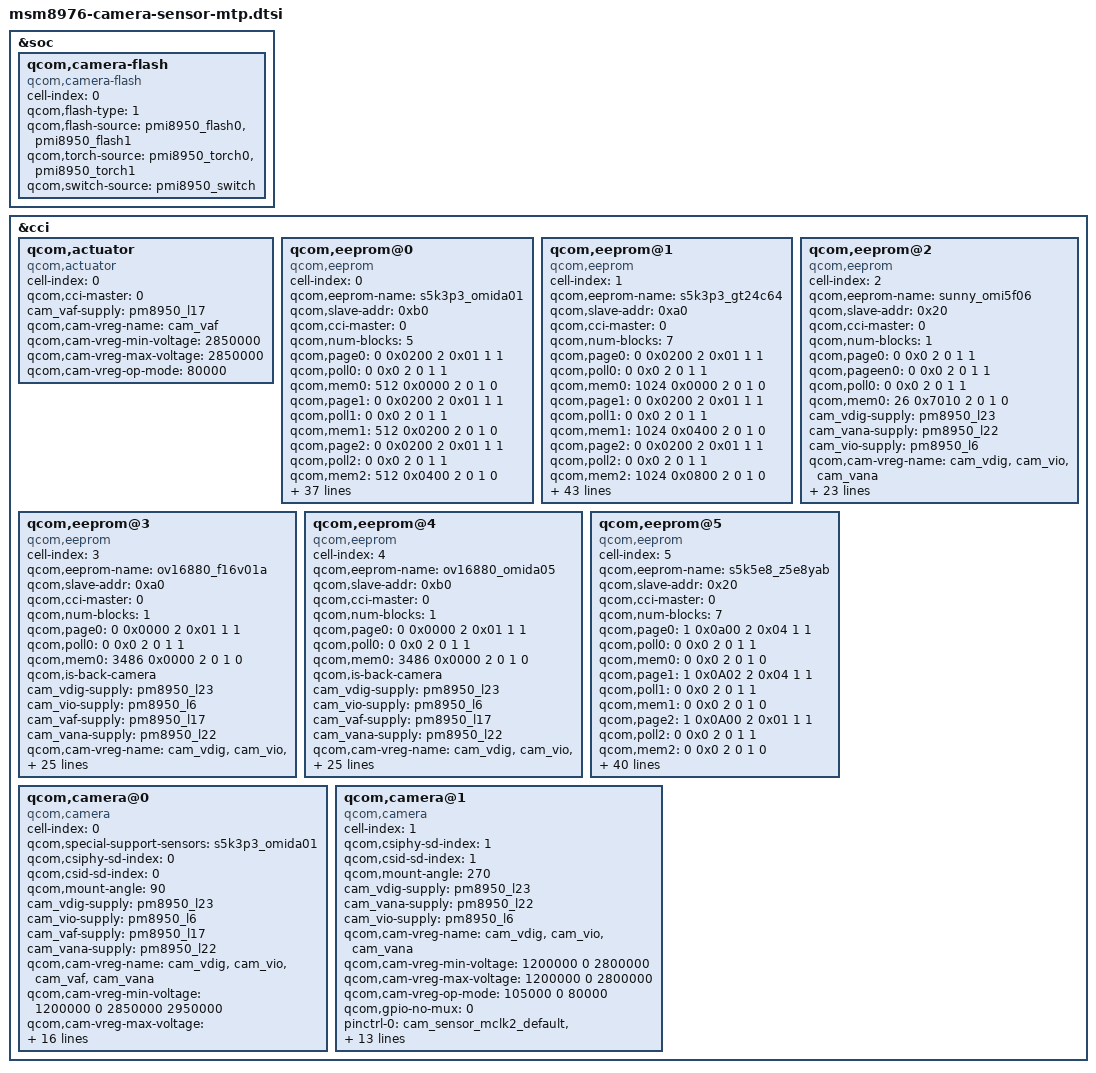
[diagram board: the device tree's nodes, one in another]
// SPDX-License-Identifier: GPL-2.0
// Copyright (c) 2015, The Linux Foundation. All rights reserved.
// Copyright (c) 2023, Benarji Anand <benarji385@gmail.com>

&soc {
	qcom,camera-flash {
		cell-index = <0>;
		compatible = "qcom,camera-flash";
		qcom,flash-type = <1>;
		qcom,flash-source = <&pmi8950_flash0 &pmi8950_flash1>;
		qcom,torch-source = <&pmi8950_torch0 &pmi8950_torch1>;
		qcom,switch-source = <&pmi8950_switch>;
	};
};

&cci {
	qcom,actuator {
		cell-index = <0>;
		compatible = "qcom,actuator";
		qcom,cci-master = <0>;
		cam_vaf-supply = <&pm8950_l17>;
		qcom,cam-vreg-name = "cam_vaf";
		qcom,cam-vreg-min-voltage = <2850000>;
		qcom,cam-vreg-max-voltage = <2850000>;
		qcom,cam-vreg-op-mode = <80000>;
	};

	qcom,eeprom@0{
		cell-index = <0>;
		qcom,eeprom-name = "s5k3p3_omida01";
		compatible = "qcom,eeprom";
		qcom,slave-addr = <0xb0>;
		qcom,cci-master = <0>;
		qcom,num-blocks = <5>;

		qcom,page0  = <0 0x0200 2 0x01 1 1>;
		qcom,poll0  = <0 0x0 2 0 1 1>;
		qcom,mem0   = <512 0x0000 2 0 1 0>;

		qcom,page1  = <0 0x0200 2 0x01 1 1>;
		qcom,poll1  = <0 0x0 2 0 1 1>;
		qcom,mem1   = <512 0x0200 2 0 1 0>;

		qcom,page2  = <0 0x0200 2 0x01 1 1>;
		qcom,poll2  = <0 0x0 2 0 1 1>;
		qcom,mem2   = <512 0x0400 2 0 1 0>;

		qcom,page3  = <0 0x0200 2 0x01 1 1>;
		qcom,poll3  = <0 0x0 2 0 1 1>;
		qcom,mem3   = <512 0x0600 2 0 1 0>;

		qcom,page4  = <0 0x0200 2 0x01 1 1>;
		qcom,poll4  = <0 0x0 2 0 1 1>;
		qcom,mem4   = <512 0x0800 2 0 1 0>;
		qcom,is-back-camera;
		cam_vdig-supply = <&pm8950_l23>;
		cam_vio-supply = <&pm8950_l6>;
		cam_vaf-supply = <&pm8950_l17>;
		cam_vana-supply = <&pm8950_l22>;  /*must add at last vreg*/
		qcom,cam-vreg-name = "cam_vdig", "cam_vio", "cam_vaf","cam_vana";
		qcom,cam-vreg-min-voltage = <1200000 0 2850000 2850000>;
		qcom,cam-vreg-max-voltage = <1200000 0 2850000 2850000>;
		qcom,cam-vreg-op-mode = <200000 0 100000 100000>;
		pinctrl-names = "cam_default", "cam_suspend";
		pinctrl-0 = <&cam_sensor_mclk0_default
				&cam_sensor_rear_default>;
		pinctrl-1 = <&cam_sensor_mclk0_sleep &cam_sensor_rear_sleep>;
		gpios = <&tlmm 26 0>,
			<&tlmm 129 0>,
			<&tlmm 123 0>;
		qcom,gpio-reset = <1>;
		qcom,gpio-vana = <2>;
		qcom,gpio-req-tbl-num = <0 1 2>;
		qcom,gpio-req-tbl-flags = <1 0 0>;
		qcom,gpio-req-tbl-label = "CAMIF_MCLK0",
			"CAM_RESET",
			"CAM_STANDBY";

		qcom,cam-power-seq-type = "sensor_vreg",
			"sensor_vreg", "sensor_vreg",
			"sensor_gpio", "sensor_gpio",
			"sensor_clk";
		qcom,cam-power-seq-val = "cam_vio",
			"cam_vana", "cam_vdig",
			"sensor_gpio_reset",
			"sensor_gpio_standby",
			"sensor_cam_mclk" ;
		qcom,cam-power-seq-cfg-val = <1 1 1 1 1 24000000>;
		qcom,cam-power-seq-delay = <5 5 5 5 5 5>;
	};

	qcom,eeprom@1{
		cell-index = <1>;
		qcom,eeprom-name = "s5k3p3_gt24c64";
		compatible = "qcom,eeprom";
		qcom,slave-addr = <0xa0>;
		qcom,cci-master = <0>;
		qcom,num-blocks = <7>;

		qcom,page0  = <0 0x0200 2 0x01 1 1>;
		qcom,poll0  = <0 0x0 2 0 1 1>;
		qcom,mem0   = <1024 0x0000 2 0 1 0>;

		qcom,page1  = <0 0x0200 2 0x01 1 1>;
		qcom,poll1  = <0 0x0 2 0 1 1>;
		qcom,mem1   = <1024 0x0400 2 0 1 0>;

		qcom,page2  = <0 0x0200 2 0x01 1 1>;
		qcom,poll2  = <0 0x0 2 0 1 1>;
		qcom,mem2   = <1024 0x0800 2 0 1 0>;

		qcom,page3  = <0 0x0200 2 0x01 1 1>;
		qcom,poll3  = <0 0x0 2 0 1 1>;
		qcom,mem3   = <1024 0x0c00 2 0 1 0>;

		qcom,page4  = <0 0x0200 2 0x01 1 1>;
		qcom,poll4  = <0 0x0 2 0 1 1>;
		qcom,mem4   = <1024 0x1000 2 0 1 0>;

		qcom,page5  = <0 0x0200 2 0x01 1 1>;
		qcom,poll5  = <0 0x0 2 0 1 1>;
		qcom,mem5   = <1024 0x1400 2 0 1 0>;

		qcom,page6  = <0 0x0200 2 0x01 1 1>;
		qcom,poll6  = <0 0x0 2 0 1 1>;
		qcom,mem6   = <1024 0x1800 2 0 1 0>;
		qcom,is-back-camera;
		cam_vdig-supply = <&pm8950_l23>;
		cam_vio-supply = <&pm8950_l6>;
		cam_vaf-supply = <&pm8950_l17>;
		cam_vana-supply = <&pm8950_l22>;  /*must add at last vreg*/
		qcom,cam-vreg-name = "cam_vdig", "cam_vio", "cam_vaf","cam_vana";
		qcom,cam-vreg-min-voltage = <1200000 0 2850000 2850000>;
		qcom,cam-vreg-max-voltage = <1200000 0 2850000 2850000>;
		qcom,cam-vreg-op-mode = <200000 0 100000 100000>;

		pinctrl-names = "cam_default", "cam_suspend";
		pinctrl-0 = <&cam_sensor_mclk0_default
				&cam_sensor_rear_default>;
		pinctrl-1 = <&cam_sensor_mclk0_sleep &cam_sensor_rear_sleep>;

		gpios = <&tlmm 26 0>,
			<&tlmm 129 0>,
			<&tlmm 123 0>;
		qcom,gpio-reset = <1>;
	        qcom,gpio-vana = <2>;
		qcom,gpio-req-tbl-num = <0 1 2>;
		qcom,gpio-req-tbl-flags = <1 0 0>;
		qcom,gpio-req-tbl-label = "CAMIF_MCLK0",
			"CAM_RESET",
			"CAM_STANDBY";

		qcom,cam-power-seq-type = "sensor_vreg",
			"sensor_vreg", "sensor_vreg",
			"sensor_gpio", "sensor_gpio",
			"sensor_clk";
		qcom,cam-power-seq-val = "cam_vio",
			"cam_vana", "cam_vdig",
			"sensor_gpio_reset",
			"sensor_gpio_standby",
			"sensor_cam_mclk" ;
		qcom,cam-power-seq-cfg-val = <1 1 1 1 1 24000000>;
		qcom,cam-power-seq-delay = <5 5 5 5 5 5>;
	};

	qcom,eeprom@2 {
		cell-index = <2>;
		qcom,eeprom-name = "sunny_omi5f06";
		compatible = "qcom,eeprom";
		qcom,slave-addr = <0x20>;
		qcom,cci-master = <0>;
		qcom,num-blocks = <1>;

		qcom,page0 = <0 0x0 2 0 1 1>;
		qcom,pageen0 = <0 0x0 2 0 1 1>;
		qcom,poll0 = <0 0x0 2 0 1 1>;
		qcom,mem0 = <26 0x7010 2 0 1 0>;

		cam_vdig-supply = <&pm8950_l23>;
		cam_vana-supply = <&pm8950_l22>;
		cam_vio-supply = <&pm8950_l6>;
		qcom,cam-vreg-name = "cam_vdig", "cam_vio", "cam_vana";
		qcom,cam-vreg-min-voltage = <1200000 0 2800000>;
		qcom,cam-vreg-max-voltage = <1200000 0 2800000>;
		qcom,cam-vreg-op-mode = <105000 0 80000>;
		qcom,gpio-no-mux = <0>;

		pinctrl-names = "cam_default", "cam_suspend";
		pinctrl-0 = <&cam_sensor_mclk2_default &cam_sensor_front1_default>;
		pinctrl-1 = <&cam_sensor_mclk2_sleep &cam_sensor_front1_sleep>;

		gpios = <&tlmm 28 0>,
			<&tlmm 131 0>,
			<&tlmm 38 0>;
		qcom,gpio-reset = <1>;
		qcom,gpio-standby = <2>;
		qcom,gpio-req-tbl-num = <0 1 2>;
		qcom,gpio-req-tbl-flags = <1 0 0>;
		qcom,gpio-req-tbl-label = "CAMIF_MCLK2",
			"CAM_RESET",
			"CAM_STANDBY";

		qcom,cam-power-seq-type = "sensor_vreg",
			"sensor_vreg", "sensor_vreg",
			"sensor_gpio", "sensor_gpio",
			"sensor_clk";
		qcom,cam-power-seq-val = "cam_vio",
			"cam_vana", "cam_vdig",
			"sensor_gpio_reset",
			"sensor_gpio_standby",
			"sensor_cam_mclk" ;
		qcom,cam-power-seq-cfg-val = <1 1 1 1 1 24000000>;
		qcom,cam-power-seq-delay = <5 5 5 5 5 5>;
	};

	qcom,eeprom@3 {
		cell-index = <3>;
		qcom,eeprom-name = "ov16880_f16v01a";
		compatible = "qcom,eeprom";
		qcom,slave-addr = <0xa0>;
		qcom,cci-master = <0>;
		qcom,num-blocks = <1>;

		qcom,page0  = <0 0x0000 2 0x01 1 1>;
		qcom,poll0  = <0 0x0 2 0 1 1>;
		qcom,mem0   = <3486 0x0000 2 0 1 0>;

		qcom,is-back-camera;
		cam_vdig-supply = <&pm8950_l23>;
		cam_vio-supply = <&pm8950_l6>;
		cam_vaf-supply = <&pm8950_l17>;
		cam_vana-supply = <&pm8950_l22>;  /*must add at last vreg*/
		qcom,cam-vreg-name = "cam_vdig", "cam_vio", "cam_vaf","cam_vana";
		qcom,cam-vreg-min-voltage = <1200000 0 2850000 2850000>;
		qcom,cam-vreg-max-voltage = <1200000 0 2850000 2850000>;
		qcom,cam-vreg-op-mode = <200000 0 100000 100000>;

		pinctrl-names = "cam_default", "cam_suspend";
		pinctrl-0 = <&cam_sensor_mclk0_default
				&cam_sensor_rear_default>;
		pinctrl-1 = <&cam_sensor_mclk0_sleep &cam_sensor_rear_sleep>;

		gpios = <&tlmm 26 0>,
			<&tlmm 129 0>,
			<&tlmm 123 0>;
		qcom,gpio-reset = <1>;
	        qcom,gpio-vana = <2>;
		qcom,gpio-req-tbl-num = <0 1 2>;
		qcom,gpio-req-tbl-flags = <1 0 0>;
		qcom,gpio-req-tbl-label = "CAMIF_MCLK0",
			"CAM_RESET",
			"CAM_STANDBY";

		qcom,cam-power-seq-type = "sensor_vreg",
			"sensor_vreg", "sensor_vreg",
			"sensor_gpio", "sensor_gpio",
			"sensor_clk";
		qcom,cam-power-seq-val = "cam_vio",
			"cam_vana", "cam_vdig",
			"sensor_gpio_reset",
			"sensor_gpio_standby",
			"sensor_cam_mclk" ;
		qcom,cam-power-seq-cfg-val = <1 1 1 1 1 24000000>;
		qcom,cam-power-seq-delay = <5 5 5 5 5 5>;
	};

	qcom,eeprom@4{
		cell-index = <4>;
		qcom,eeprom-name = "ov16880_omida05";
		compatible = "qcom,eeprom";
		qcom,slave-addr = <0xb0>;
		qcom,cci-master = <0>;
		qcom,num-blocks = <1>;

		qcom,page0  = <0 0x0000 2 0x01 1 1>;
		qcom,poll0  = <0 0x0 2 0 1 1>;
		qcom,mem0   = <3486 0x0000 2 0 1 0>;

		qcom,is-back-camera;
		cam_vdig-supply = <&pm8950_l23>;
		cam_vio-supply = <&pm8950_l6>;
		cam_vaf-supply = <&pm8950_l17>;
		cam_vana-supply = <&pm8950_l22>;  /*must add at last vreg*/
		qcom,cam-vreg-name = "cam_vdig", "cam_vio", "cam_vaf","cam_vana";
		qcom,cam-vreg-min-voltage = <1200000 0 2850000 2850000>;
		qcom,cam-vreg-max-voltage = <1200000 0 2850000 2850000>;
		qcom,cam-vreg-op-mode = <200000 0 100000 100000>;

		pinctrl-names = "cam_default", "cam_suspend";
		pinctrl-0 = <&cam_sensor_mclk0_default
				&cam_sensor_rear_default>;
		pinctrl-1 = <&cam_sensor_mclk0_sleep &cam_sensor_rear_sleep>;

		gpios = <&tlmm 26 0>,
			<&tlmm 129 0>,
			<&tlmm 123 0>;
		qcom,gpio-reset = <1>;
	        qcom,gpio-vana = <2>;
		qcom,gpio-req-tbl-num = <0 1 2>;
		qcom,gpio-req-tbl-flags = <1 0 0>;
		qcom,gpio-req-tbl-label = "CAMIF_MCLK0",
			"CAM_RESET",
			"CAM_STANDBY";

		qcom,cam-power-seq-type = "sensor_vreg",
			"sensor_vreg", "sensor_vreg",
			"sensor_gpio", "sensor_gpio",
			"sensor_clk";
		qcom,cam-power-seq-val = "cam_vio",
			"cam_vana", "cam_vdig",
			"sensor_gpio_reset",
			"sensor_gpio_standby",
			"sensor_cam_mclk" ;
		qcom,cam-power-seq-cfg-val = <1 1 1 1 1 24000000>;
		qcom,cam-power-seq-delay = <5 5 5 5 5 5>;
	};

	qcom,eeprom@5 {
		cell-index = <5>;
		qcom,eeprom-name = "s5k5e8_z5e8yab";
		compatible = "qcom,eeprom";
		qcom,slave-addr = <0x20>;
		qcom,cci-master = <0>;
		qcom,num-blocks = <7>;

		qcom,page0 = <1 0x0a00 2 0x04 1 1>;
		qcom,poll0 = <0 0x0 2 0 1 1>;
		qcom,mem0 = <0 0x0 2 0 1 0>;

		qcom,page1 = <1 0x0A02 2 0x04 1 1>;
		qcom,poll1 = <0 0x0 2 0 1 1>;
		qcom,mem1 = <0 0x0 2 0 1 0>;

		qcom,page2 = <1 0x0A00 2 0x01 1 1>;
		qcom,poll2 = <0 0x0 2 0 1 1>;
		qcom,mem2 = <0 0x0 2 0 1 0>;

		qcom,page3 = <0 0x0A02 2 0x04 1 1>;
		qcom,poll3 = <0 0x0 2 0 1 1>;
		qcom,mem3 = <64 0x0A04 2 0 1 0>;

		qcom,page4 = <1 0x0A02 2 0x05 1 1>;
		qcom,poll4 = <0 0x0 2 0 1 1>;
		qcom,mem4 = <0 0x0 2 0 1 0>;

		qcom,page5 = <1 0x0A00 2 0x01 1 1>;
		qcom,poll5 = <0 0x0 2 0 1 1>;
		qcom,mem5 = <0 0x0 2 0 1 0>;

		qcom,page6 = <0 0x0A02 2 0x05 1 1>;
		qcom,poll6 = <0 0x0 2 0 1 1>;
		qcom,mem6 = <64 0x0A04 2 0 1 0>;

		cam_vdig-supply = <&pm8950_l23>;
                cam_vana-supply = <&pm8950_l22>;
		cam_vio-supply = <&pm8950_l6>;
		qcom,cam-vreg-name = "cam_vdig", "cam_vio", "cam_vana";
		qcom,cam-vreg-min-voltage = <1200000 0 2800000>;
		qcom,cam-vreg-max-voltage = <1200000 0 2800000>;
		qcom,cam-vreg-op-mode = <105000 0 80000>;
		qcom,gpio-no-mux = <0>;

		pinctrl-names = "cam_default", "cam_suspend";
		pinctrl-0 = <&cam_sensor_mclk2_default &cam_sensor_front1_default>;
		pinctrl-1 = <&cam_sensor_mclk2_sleep &cam_sensor_front1_sleep>;

		gpios = <&tlmm 28 0>,
			<&tlmm 131 0>,
			<&tlmm 38 0>;
		qcom,gpio-reset = <1>;
		qcom,gpio-standby = <2>;
		qcom,gpio-req-tbl-num = <0 1 2>;
		qcom,gpio-req-tbl-flags = <1 0 0>;
		qcom,gpio-req-tbl-label = "CAMIF_MCLK2",
			"CAM_RESET",
			"CAM_STANDBY";

		qcom,cam-power-seq-type = "sensor_vreg",
			"sensor_vreg", "sensor_vreg",
			"sensor_gpio", "sensor_gpio",
			"sensor_clk";
		qcom,cam-power-seq-val = "cam_vio",
			"cam_vana", "cam_vdig",
			"sensor_gpio_reset",
			"sensor_gpio_standby",
			"sensor_cam_mclk" ;
		qcom,cam-power-seq-cfg-val = <1 1 1 1 1 24000000>;
		qcom,cam-power-seq-delay = <5 5 5 5 5 5>;
	};

	qcom,camera@0 {
		cell-index = <0>;
		compatible = "qcom,camera";
		qcom,special-support-sensors = "s5k3p3_omida01";
		qcom,csiphy-sd-index = <0>;
		qcom,csid-sd-index = <0>;
		qcom,mount-angle = <90>;
		cam_vdig-supply = <&pm8950_l23>;
		cam_vio-supply = <&pm8950_l6>;
		cam_vaf-supply = <&pm8950_l17>;
		cam_vana-supply = <&pm8950_l22>;/*must add at last vreg*/
		qcom,cam-vreg-name = "cam_vdig", "cam_vio","cam_vaf","cam_vana";
		qcom,cam-vreg-min-voltage = <1200000 0 2850000 2950000>;
		qcom,cam-vreg-max-voltage = <1200000 0 2850000 2950000>;
		qcom,cam-vreg-op-mode = <200000 0 100000 100000>;

		pinctrl-names = "cam_default", "cam_suspend";
		pinctrl-0 = <&cam_sensor_mclk0_default
				&cam_sensor_rear_default>;
		pinctrl-1 = <&cam_sensor_mclk0_sleep &cam_sensor_rear_sleep>;

		gpios = <&tlmm 26 0>,
			<&tlmm 129 0>,
			<&tlmm 123 0>;
		qcom,gpio-reset = <1>;
		qcom,gpio-vana = <2>;
		qcom,gpio-req-tbl-num = <0 1 2>;
		qcom,gpio-req-tbl-flags = <1 0 0>;
		qcom,gpio-req-tbl-label = "CAMIF_MCLK0",
			"CAM_RESET",
			"CAM_STANDBY";

		qcom,sensor-position = <0>;
		qcom,sensor-mode = <0>;
		qcom,cci-master = <0>;
	};

	qcom,camera@1 {
		cell-index = <1>;
		compatible = "qcom,camera";
		qcom,csiphy-sd-index = <1>;
		qcom,csid-sd-index = <1>;
		qcom,mount-angle = <270>;
		cam_vdig-supply = <&pm8950_l23>;
		cam_vana-supply = <&pm8950_l22>;
		cam_vio-supply = <&pm8950_l6>;
		qcom,cam-vreg-name = "cam_vdig", "cam_vio", "cam_vana";
		qcom,cam-vreg-min-voltage = <1200000 0 2800000>;
		qcom,cam-vreg-max-voltage = <1200000 0 2800000>;
		qcom,cam-vreg-op-mode = <105000 0 80000>;
		qcom,gpio-no-mux = <0>;

		pinctrl-names = "cam_default", "cam_suspend";
		pinctrl-0 = <&cam_sensor_mclk2_default &cam_sensor_front1_default>;
		pinctrl-1 = <&cam_sensor_mclk2_sleep &cam_sensor_front1_sleep>;

		gpios = <&tlmm 28 0>,
			<&tlmm 131 0>,
			<&tlmm 38 0>;
		qcom,gpio-reset = <1>;
		qcom,gpio-standby = <2>;
		qcom,gpio-req-tbl-num = <0 1 2>;
		qcom,gpio-req-tbl-flags = <1 0 0>;
		qcom,gpio-req-tbl-label = "CAMIF_MCLK2",
			"CAM_RESET",
			"CAM_STANDBY";

		qcom,sensor-position = <1>;
		qcom,sensor-mode = <0>;
		qcom,cci-master = <0>;
	};
};
